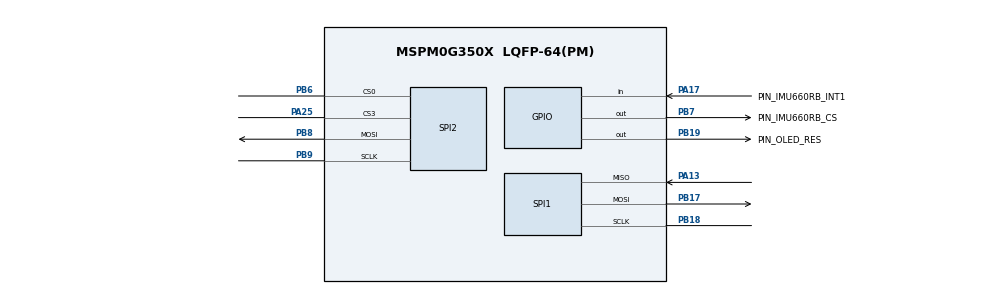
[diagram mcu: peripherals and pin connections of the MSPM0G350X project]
/**
 * @cliArgs --device "MSPM0G350X" --part "Default" --package "LQFP-64(PM)" --product "mspm0_sdk@2.05.01.00"
 * @versions {"tool":"1.24.0+4110"}
 */

/**
 * Import the modules used in this configuration.
 */
const GPIO   = scripting.addModule("/ti/driverlib/GPIO", {}, false);
const GPIO1  = GPIO.addInstance();
const GPIO2  = GPIO.addInstance();
const SPI    = scripting.addModule("/ti/driverlib/SPI", {}, false);
const SPI1   = SPI.addInstance();
const SPI2   = SPI.addInstance();
const SYSCTL = scripting.addModule("/ti/driverlib/SYSCTL");

/**
 * Write custom configuration values to the imported modules.
 */
const divider7       = system.clockTree["PLL_PDIV"];
divider7.divideValue = 2;

const divider9       = system.clockTree["UDIV"];
divider9.divideValue = 2;

const multiplier2         = system.clockTree["PLL_QDIV"];
multiplier2.multiplyValue = 5;

const mux8       = system.clockTree["HSCLKMUX"];
mux8.inputSelect = "HSCLKMUX_SYSPLL2X";

GPIO1.$name                               = "GPIO_IMU660RB";
GPIO1.associatedPins.create(2);
GPIO1.associatedPins[0].$name             = "PIN_IMU660RB_CS";
GPIO1.associatedPins[0].pin.$assign       = "PB7";
GPIO1.associatedPins[1].$name             = "PIN_IMU660RB_INT1";
GPIO1.associatedPins[1].direction         = "INPUT";
GPIO1.associatedPins[1].interruptEn       = true;
GPIO1.associatedPins[1].interruptPriority = "3";
GPIO1.associatedPins[1].polarity          = "RISE";
GPIO1.associatedPins[1].pin.$assign       = "PA17";

const Board = scripting.addModule("/ti/driverlib/Board", {}, false);

GPIO2.$name                         = "GPIO_OLED";
GPIO2.associatedPins[0].$name       = "PIN_OLED_RES";
GPIO2.associatedPins[0].pin.$assign = "PB19";

SPI1.$name                              = "SPI_IMU660RB";
SPI1.chipSelect                         = ["2"];
SPI1.frameFormat                        = "MOTO3";
SPI1.sclkPinConfig.$name                = "ti_driverlib_gpio_GPIOPinGeneric0";
SPI1.sclkPinConfig.direction            = scripting.forceWrite("OUTPUT");
SPI1.sclkPinConfig.onlyInternalResistor = scripting.forceWrite(false);
SPI1.sclkPinConfig.passedPeripheralType = scripting.forceWrite("Digital");
SPI1.mosiPinConfig.$name                = "ti_driverlib_gpio_GPIOPinGeneric1";
SPI1.mosiPinConfig.direction            = scripting.forceWrite("OUTPUT");
SPI1.mosiPinConfig.hideOutputInversion  = scripting.forceWrite(false);
SPI1.mosiPinConfig.onlyInternalResistor = scripting.forceWrite(false);
SPI1.mosiPinConfig.passedPeripheralType = scripting.forceWrite("Digital");
SPI1.misoPinConfig.$name                = "ti_driverlib_gpio_GPIOPinGeneric2";
SPI1.misoPinConfig.onlyInternalResistor = scripting.forceWrite(false);
SPI1.misoPinConfig.passedPeripheralType = scripting.forceWrite("Digital");
SPI1.peripheral.$assign                 = "SPI0";
SPI1.peripheral.sclkPin.$assign         = "PB18";
SPI1.peripheral.mosiPin.$assign         = "PB17";
SPI1.peripheral.misoPin.$assign         = "PA13";

SPI2.$name                              = "SPI_OLED";
SPI2.targetBitRate                      = 10000000;
SPI2.direction                          = "PICO";
SPI2.enableCDMode                       = true;
SPI2.sclkPinConfig.direction            = scripting.forceWrite("OUTPUT");
SPI2.sclkPinConfig.onlyInternalResistor = scripting.forceWrite(false);
SPI2.sclkPinConfig.passedPeripheralType = scripting.forceWrite("Digital");
SPI2.sclkPinConfig.$name                = "ti_driverlib_gpio_GPIOPinGeneric3";
SPI2.mosiPinConfig.direction            = scripting.forceWrite("OUTPUT");
SPI2.mosiPinConfig.hideOutputInversion  = scripting.forceWrite(false);
SPI2.mosiPinConfig.onlyInternalResistor = scripting.forceWrite(false);
SPI2.mosiPinConfig.passedPeripheralType = scripting.forceWrite("Digital");
SPI2.mosiPinConfig.$name                = "ti_driverlib_gpio_GPIOPinGeneric4";
SPI2.cs0PinConfig.direction             = scripting.forceWrite("OUTPUT");
SPI2.cs0PinConfig.hideOutputInversion   = scripting.forceWrite(false);
SPI2.cs0PinConfig.onlyInternalResistor  = scripting.forceWrite(false);
SPI2.cs0PinConfig.passedPeripheralType  = scripting.forceWrite("Digital");
SPI2.cs0PinConfig.$name                 = "ti_driverlib_gpio_GPIOPinGeneric6";
SPI2.peripheral.$assign                 = "SPI1";
SPI2.peripheral.sclkPin.$assign         = "PB9";
SPI2.peripheral.mosiPin.$assign         = "PB8";
SPI2.peripheral.cs0Pin.$assign          = "PB6";
SPI2.peripheral.cs3Pin.$assign          = "PA25";
SPI2.cs3PinConfig.$name                 = "ti_driverlib_gpio_GPIOPinGeneric5";

SYSCTL.forceDefaultClkConfig = true;
SYSCTL.clockTreeEn           = true;
scripting.suppress("For best practices when the CPUCLK is running at 32MHz and above, clear the flash status bit using DL_FlashCTL_executeClearStatus\\(\\) before executing any flash operation\\. Otherwise there may be false positives\\.", SYSCTL);

/**
 * Pinmux solution for unlocked pins/peripherals. This ensures that minor changes to the automatic solver in a future
 * version of the tool will not impact the pinmux you originally saw.  These lines can be completely deleted in order to
 * re-solve from scratch.
 */
Board.peripheral.$suggestSolution          = "DEBUGSS";
Board.peripheral.swclkPin.$suggestSolution = "PA20";
Board.peripheral.swdioPin.$suggestSolution = "PA19";
